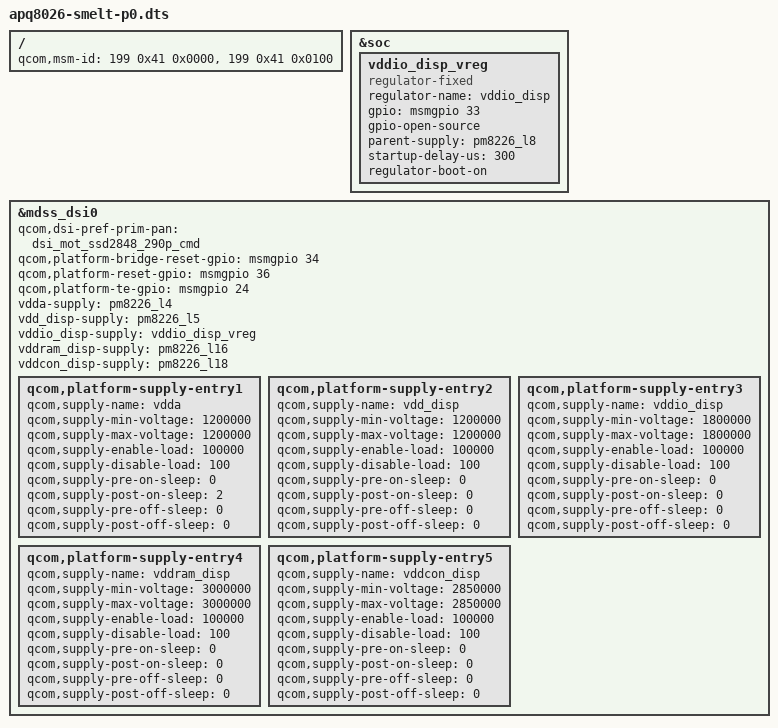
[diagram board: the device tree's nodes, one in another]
/* Copyright (c) 2014, The Linux Foundation. All rights reserved.
 *
 * This program is free software; you can redistribute it and/or modify
 * it under the terms of the GNU General Public License version 2 and
 * only version 2 as published by the Free Software Foundation.
 *
 * This program is distributed in the hope that it will be useful,
 * but WITHOUT ANY WARRANTY; without even the implied warranty of
 * MERCHANTABILITY or FITNESS FOR A PARTICULAR PURPOSE.  See the
 * GNU General Public License for more details.
 */

/dts-v1/;

#include "apq8026-smelt-common.dtsi"

/ {
	qcom,msm-id =
		<199 0x41 0x0000>, /* P0 Wingboard */
		<199 0x41 0x0100>; /* P0 Portable */
};

&soc {
	vddio_disp_vreg: vddio_disp_vreg {
		compatible = "regulator-fixed";
		regulator-name = "vddio_disp";
		gpio = <&msmgpio 33 0x0>;
		gpio-open-source;
		parent-supply = <&pm8226_l8>;
		startup-delay-us = <300>;
		regulator-boot-on;
	};
};

&mdss_dsi0 {
	qcom,dsi-pref-prim-pan = <&dsi_mot_ssd2848_290p_cmd>;
	qcom,platform-bridge-reset-gpio = <&msmgpio 34 0>;
	qcom,platform-reset-gpio = <&msmgpio 36 0>;
	qcom,platform-te-gpio = <&msmgpio 24 0>;
	vdda-supply = <&pm8226_l4>;
	vdd_disp-supply = <&pm8226_l5>;
	vddio_disp-supply = <&vddio_disp_vreg>;
	vddram_disp-supply = <&pm8226_l16>;
	vddcon_disp-supply = <&pm8226_l18>;
	qcom,platform-supply-entry1 {
		qcom,supply-name = "vdda";
		qcom,supply-min-voltage = <1200000>;
		qcom,supply-max-voltage = <1200000>;
		qcom,supply-enable-load = <100000>;
		qcom,supply-disable-load = <100>;
		qcom,supply-pre-on-sleep = <0>;
		qcom,supply-post-on-sleep = <2>;
		qcom,supply-pre-off-sleep = <0>;
		qcom,supply-post-off-sleep = <0>;
	};
	qcom,platform-supply-entry2 {
		qcom,supply-name = "vdd_disp";
		qcom,supply-min-voltage = <1200000>;
		qcom,supply-max-voltage = <1200000>;
		qcom,supply-enable-load = <100000>;
		qcom,supply-disable-load = <100>;
		qcom,supply-pre-on-sleep = <0>;
		qcom,supply-post-on-sleep = <0>;
		qcom,supply-pre-off-sleep = <0>;
		qcom,supply-post-off-sleep = <0>;
	};
	qcom,platform-supply-entry3 {
		qcom,supply-name = "vddio_disp";
		qcom,supply-min-voltage = <1800000>;
		qcom,supply-max-voltage = <1800000>;
		qcom,supply-enable-load = <100000>;
		qcom,supply-disable-load = <100>;
		qcom,supply-pre-on-sleep = <0>;
		qcom,supply-post-on-sleep = <0>;
		qcom,supply-pre-off-sleep = <0>;
		qcom,supply-post-off-sleep = <0>;
	};
	qcom,platform-supply-entry4 {
		qcom,supply-name = "vddram_disp";
		qcom,supply-min-voltage = <3000000>;
		qcom,supply-max-voltage = <3000000>;
		qcom,supply-enable-load = <100000>;
		qcom,supply-disable-load = <100>;
		qcom,supply-pre-on-sleep = <0>;
		qcom,supply-post-on-sleep = <0>;
		qcom,supply-pre-off-sleep = <0>;
		qcom,supply-post-off-sleep = <0>;
	};
	qcom,platform-supply-entry5 {
		qcom,supply-name = "vddcon_disp";
		qcom,supply-min-voltage = <2850000>;
		qcom,supply-max-voltage = <2850000>;
		qcom,supply-enable-load = <100000>;
		qcom,supply-disable-load = <100>;
		qcom,supply-pre-on-sleep = <0>;
		qcom,supply-post-on-sleep = <0>;
		qcom,supply-pre-off-sleep = <0>;
		qcom,supply-post-off-sleep = <0>;
	};
};
